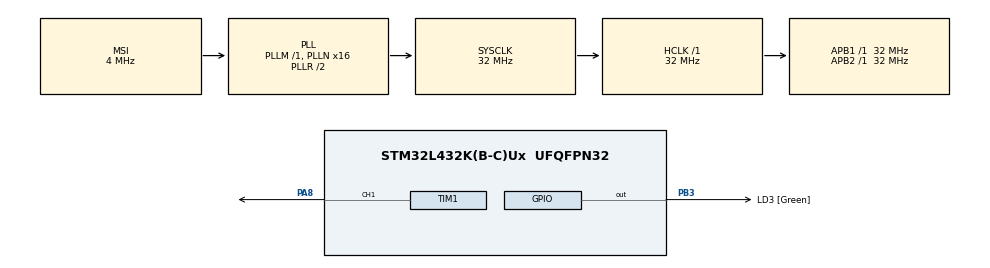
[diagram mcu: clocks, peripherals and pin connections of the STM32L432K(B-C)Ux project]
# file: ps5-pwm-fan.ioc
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Mcu.Family=STM32L4
Mcu.Name=STM32L432K(B-C)Ux
Mcu.Package=UFQFPN32
NVIC.PriorityGroup=NVIC_PRIORITYGROUP_4
PA0.GPIO_Label=MCO [High speed clock in]
PA0.Signal=RCC_CK_IN
PA13\ (JTMS-SWDIO).GPIO_Label=SWDIO
PA13\ (JTMS-SWDIO).Signal=SYS_JTMS-SWDIO
PA14\ (JTCK-SWCLK).GPIO_Label=SWCLK
PA14\ (JTCK-SWCLK).Signal=SYS_JTCK-SWCLK
PA15\ (JTDI).GPIO_Label=VCP_RX
PA15\ (JTDI).Signal=USART2_RX
PA2.GPIO_Label=VCP_TX
PA2.Signal=USART2_TX
PA8.Signal=S_TIM1_CH1
PB3\ (JTDO-TRACESWO).GPIO_Label=LD3 [Green]
PB3\ (JTDO-TRACESWO).Signal=GPIO_Output
PC14-OSC32_IN\ (PC14).Signal=RCC_OSC32_IN
PC15-OSC32_OUT\ (PC15).Signal=RCC_OSC32_OUT
ProjectManager.HeapSize=0x200
ProjectManager.StackSize=0x400
ProjectManager.TargetToolchain=STM32CubeIDE
RCC.AHBFreq_Value=32000000
RCC.APB1Freq_Value=32000000
RCC.APB1TimFreq_Value=32000000
RCC.APB2Freq_Value=32000000
RCC.APB2TimFreq_Value=32000000
RCC.CortexFreq_Value=32000000
RCC.HCLKFreq_Value=32000000
RCC.HSE_VALUE=8000000
RCC.HSI16_VALUE=16000000
RCC.HSI48_VALUE=48000000
RCC.HSI_VALUE=16000000
RCC.LSE_VALUE=32768
RCC.MSI_VALUE=4000000
RCC.PLLMUL=RCC_PLLMUL_4
RCC.PLLN=16
RCC.SYSCLKFreq_VALUE=32000000
RCC.SYSCLKSource=RCC_SYSCLKSOURCE_PLLCLK
RCC.VCOOutputFreq_Value=64000000
SH.S_TIM1_CH1.0=TIM1_CH1,PWM Generation1 CH1
TIM1.Channel-PWM\ Generation1\ CH1=TIM_CHANNEL_1
TIM1.Period=3199
VP_TIM1_VS_ClockSourceINT.Mode=Internal
board=NUCLEO-L432KC

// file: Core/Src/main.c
/* USER CODE BEGIN Header */
/**
  ******************************************************************************
  * @file           : main.c
  * @brief          : Main program body
  ******************************************************************************
  * @attention
  *
  * Copyright (c) 2026 STMicroelectronics.
  * All rights reserved.
  *
  * This software is licensed under terms that can be found in the LICENSE file
  * in the root directory of this software component.
  * If no LICENSE file comes with this software, it is provided AS-IS.
  *
  ******************************************************************************
  */
/* USER CODE END Header */
#include "main.h"
#include "tim.h"
#include "gpio.h"

void SystemClock_Config(void);
/* USER CODE BEGIN PFP */
void Set_Fan_Speed(uint8_t percent);
/* USER CODE END PFP */

int main(void)
{

  /* MCU Configuration--------------------------------------------------------*/

  /* Reset of all peripherals, Initializes the Flash interface and the Systick. */
  HAL_Init();

  /* Configure the system clock */
  SystemClock_Config();

  /* Initialize all configured peripherals */
  MX_GPIO_Init();
  MX_TIM1_Init();
  /* USER CODE BEGIN 2 */
  HAL_TIM_PWM_Start(&htim1, TIM_CHANNEL_1);
  /* USER CODE END 2 */

  /* Infinite loop */
  /* USER CODE BEGIN WHILE */
  while (1)
  {
	  Set_Fan_Speed(25);  // Low speed
	      HAL_Delay(5000);

	      Set_Fan_Speed(75);  // High speed
	      HAL_Delay(5000);
    /* USER CODE END WHILE */

  }
}

void SystemClock_Config(void)
{
  RCC_OscInitTypeDef RCC_OscInitStruct = {0};
  RCC_ClkInitTypeDef RCC_ClkInitStruct = {0};

  /** Configure the main internal regulator output voltage
  */
  if (HAL_PWREx_ControlVoltageScaling(PWR_REGULATOR_VOLTAGE_SCALE1) != HAL_OK)
  {
    Error_Handler();
  }

  /** Initializes the RCC Oscillators according to the specified parameters
  * in the RCC_OscInitTypeDef structure.
  */
  RCC_OscInitStruct.OscillatorType = RCC_OSCILLATORTYPE_MSI;
  RCC_OscInitStruct.MSIState = RCC_MSI_ON;
  RCC_OscInitStruct.MSICalibrationValue = 0;
  RCC_OscInitStruct.MSIClockRange = RCC_MSIRANGE_6;
  RCC_OscInitStruct.PLL.PLLState = RCC_PLL_ON;
  RCC_OscInitStruct.PLL.PLLSource = RCC_PLLSOURCE_MSI;
  RCC_OscInitStruct.PLL.PLLM = 1;
  RCC_OscInitStruct.PLL.PLLN = 16;
  RCC_OscInitStruct.PLL.PLLP = RCC_PLLP_DIV7;
  RCC_OscInitStruct.PLL.PLLQ = RCC_PLLQ_DIV2;
  RCC_OscInitStruct.PLL.PLLR = RCC_PLLR_DIV2;
  if (HAL_RCC_OscConfig(&RCC_OscInitStruct) != HAL_OK)
  {
    Error_Handler();
  }

  /** Initializes the CPU, AHB and APB buses clocks
  */
  RCC_ClkInitStruct.ClockType = RCC_CLOCKTYPE_HCLK|RCC_CLOCKTYPE_SYSCLK
                              |RCC_CLOCKTYPE_PCLK1|RCC_CLOCKTYPE_PCLK2;
  RCC_ClkInitStruct.SYSCLKSource = RCC_SYSCLKSOURCE_PLLCLK;
  RCC_ClkInitStruct.AHBCLKDivider = RCC_SYSCLK_DIV1;
  RCC_ClkInitStruct.APB1CLKDivider = RCC_HCLK_DIV1;
  RCC_ClkInitStruct.APB2CLKDivider = RCC_HCLK_DIV1;

  if (HAL_RCC_ClockConfig(&RCC_ClkInitStruct, FLASH_LATENCY_1) != HAL_OK)
  {
    Error_Handler();
  }
}

/* USER CODE BEGIN 4 */
/**
 * @brief Sets the fan speed from 0 to 100 percent.
 * @param percent: integer from 0 to 100
 */
void Set_Fan_Speed(uint8_t percent) {
    if (percent > 100) percent = 100;

    // Formula: (Percent / 100) * ARR
    uint32_t pulse = (percent * 3199) / 100;

    __HAL_TIM_SET_COMPARE(&htim1, TIM_CHANNEL_1, pulse);
}
/* USER CODE END 4 */

void Error_Handler(void)
{
  __disable_irq();
  while (1)
  {
  }
}
